VERSION ""

NS_ :

BS_:

BU_: Engine
VAL_TABLE_ engine_oil_warning 1 "oil_low" 0 "ok" ;

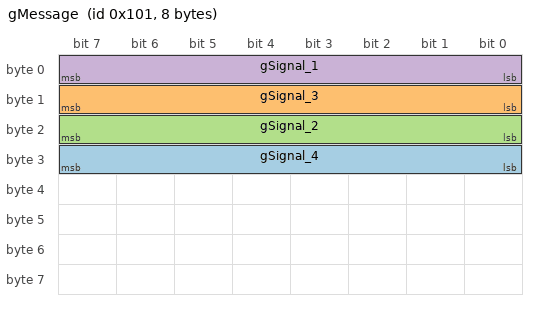
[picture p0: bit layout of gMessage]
BO_ 257 gMessage: 8 Engine
 SG_ gSignal_4 : 24|8@1+ (1,0) [0|125] "" Vector__XXX
 SG_ gSignal_3 : 8|8@1+ (1,0) [0|125] "" Vector__XXX
 SG_ gSignal_2 : 16|8@1+ (1,0) [0|125] "" Vector__XXX
 SG_ gSignal_1 : 0|8@1+ (1,0) [0|125] "" Vector__XXX

BO_ 258 iMessage: 8 Engine
 SG_ iSignal_3 m1 : 8|24@1+ (1,0) [0|125] "" Vector__XXX
 SG_ iSignal_5 m2 : 8|24@1+ (1,0) [0|125] "" Vector__XXX
 SG_ iSignal_4 m1 : 32|24@1+ (1,0) [0|125] "" Vector__XXX
 SG_ iSignal_2 m0 : 32|24@1+ (1,0) [0|125] "" Vector__XXX
 SG_ iSignal_1 m0 : 8|24@1+ (1,0) [0|125] "" Vector__XXX
 SG_ iSignal_mux M : 0|8@1+ (1,0) [0|2] "" Vector__XXX

BO_ 256 engine_warning: 8 Engine
 SG_ engine_oil_low : 0|1@1+ (1,0) [0|1] "" Vector__XXX

BA_DEF_  "BusType" STRING ;
BA_DEF_DEF_  "BusType" "CAN";
VAL_ 256 engine_oil_low 1 "oil_low" 0 "ok" ;
SIG_GROUP_ 257 Signal_Group_2 1 : gSignal_4 gSignal_3;
SIG_GROUP_ 257 Signal_Group_1 1 : gSignal_2 gSignal_1;
